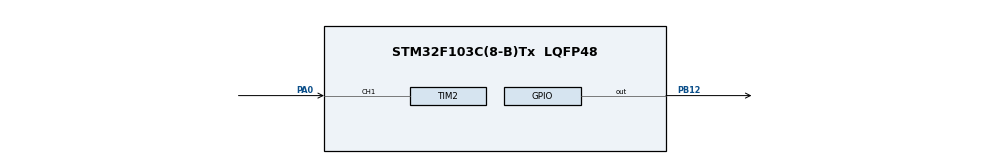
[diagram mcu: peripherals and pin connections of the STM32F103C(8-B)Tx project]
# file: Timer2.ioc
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Mcu.Family=STM32F1
Mcu.Name=STM32F103C(8-B)Tx
Mcu.Package=LQFP48
NVIC.PriorityGroup=NVIC_PRIORITYGROUP_4
PA0-WKUP.Signal=S_TIM2_CH1_ETR
PB12.Signal=GPIO_Output
ProjectManager.HeapSize=0x200
ProjectManager.StackSize=0x400
ProjectManager.TargetToolchain=MDK-ARM V4
RCC.APB1Freq_Value=8000000
RCC.APB2Freq_Value=8000000
SH.S_TIM2_CH1_ETR.0=TIM2_CH1,TriggerSource_TI1FP1
TIM2.Period=1000
TIM2.Slave_TriggerFilter=15
TIM2.Slave_TriggerPolarity=TIM_TRIGGERPOLARITY_RISING
VP_TIM2_VS_ControllerModeClock.Mode=Clock Mode
board=Timer2

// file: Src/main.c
/**
  ******************************************************************************
  * File Name          : main.c
  * Description        : Main program body
  ******************************************************************************
  *
  * COPYRIGHT(c) 2016 STMicroelectronics
  *
  * Redistribution and use in source and binary forms, with or without modification,
  * are permitted provided that the following conditions are met:
  *   1. Redistributions of source code must retain the above copyright notice,
  *      this list of conditions and the following disclaimer.
  *   2. Redistributions in binary form must reproduce the above copyright notice,
  *      this list of conditions and the following disclaimer in the documentation
  *      and/or other materials provided with the distribution.
  *   3. Neither the name of STMicroelectronics nor the names of its contributors
  *      may be used to endorse or promote products derived from this software
  *      without specific prior written permission.
  *
  * THIS SOFTWARE IS PROVIDED BY THE COPYRIGHT HOLDERS AND CONTRIBUTORS "AS IS"
  * AND ANY EXPRESS OR IMPLIED WARRANTIES, INCLUDING, BUT NOT LIMITED TO, THE
  * IMPLIED WARRANTIES OF MERCHANTABILITY AND FITNESS FOR A PARTICULAR PURPOSE ARE
  * DISCLAIMED. IN NO EVENT SHALL THE COPYRIGHT HOLDER OR CONTRIBUTORS BE LIABLE
  * FOR ANY DIRECT, INDIRECT, INCIDENTAL, SPECIAL, EXEMPLARY, OR CONSEQUENTIAL
  * DAMAGES (INCLUDING, BUT NOT LIMITED TO, PROCUREMENT OF SUBSTITUTE GOODS OR
  * SERVICES; LOSS OF USE, DATA, OR PROFITS; OR BUSINESS INTERRUPTION) HOWEVER
  * CAUSED AND ON ANY THEORY OF LIABILITY, WHETHER IN CONTRACT, STRICT LIABILITY,
  * OR TORT (INCLUDING NEGLIGENCE OR OTHERWISE) ARISING IN ANY WAY OUT OF THE USE
  * OF THIS SOFTWARE, EVEN IF ADVISED OF THE POSSIBILITY OF SUCH DAMAGE.
  *
  ******************************************************************************
  */
#include "stm32f1xx_hal.h"

TIM_HandleTypeDef htim2;

/* USER CODE BEGIN PV */
/* Private variables ---------------------------------------------------------*/
long count = 0;
/* USER CODE END PV */

void SystemClock_Config(void);
static void MX_GPIO_Init(void);
static void MX_TIM2_Init(void);

/* USER CODE BEGIN PFP */
/* Private function prototypes -----------------------------------------------*/

/* USER CODE END PFP */

int main(void)
{

  /* MCU Configuration----------------------------------------------------------*/

  /* Reset of all peripherals, Initializes the Flash interface and the Systick. */
  HAL_Init();

  /* Configure the system clock */
  SystemClock_Config();

  /* Initialize all configured peripherals */
  MX_GPIO_Init();
  MX_TIM2_Init();

  /* USER CODE BEGIN 2 */
	HAL_TIM_Base_Start(&htim2);// Khoi dong timer 2 khong su dung ngat
  /* USER CODE END 2 */

  /* Infinite loop */
  while (1)
  {
	count = __HAL_TIM_GetCounter(&htim2); // Doc gia tri bien count cua Timer2
  }

}

/** System Clock Configuration
*/
void SystemClock_Config(void)
{

  RCC_OscInitTypeDef RCC_OscInitStruct;
  RCC_ClkInitTypeDef RCC_ClkInitStruct;

  RCC_OscInitStruct.OscillatorType = RCC_OSCILLATORTYPE_HSI;
  RCC_OscInitStruct.HSIState = RCC_HSI_ON;
  RCC_OscInitStruct.HSICalibrationValue = 16;
  RCC_OscInitStruct.PLL.PLLState = RCC_PLL_NONE;
  HAL_RCC_OscConfig(&RCC_OscInitStruct);

  RCC_ClkInitStruct.ClockType = RCC_CLOCKTYPE_HCLK|RCC_CLOCKTYPE_SYSCLK
                              |RCC_CLOCKTYPE_PCLK1|RCC_CLOCKTYPE_PCLK2;
  RCC_ClkInitStruct.SYSCLKSource = RCC_SYSCLKSOURCE_HSI;
  RCC_ClkInitStruct.AHBCLKDivider = RCC_SYSCLK_DIV1;
  RCC_ClkInitStruct.APB1CLKDivider = RCC_HCLK_DIV1;
  RCC_ClkInitStruct.APB2CLKDivider = RCC_HCLK_DIV1;
  HAL_RCC_ClockConfig(&RCC_ClkInitStruct, FLASH_LATENCY_0);

  HAL_SYSTICK_Config(HAL_RCC_GetHCLKFreq()/1000);

  HAL_SYSTICK_CLKSourceConfig(SYSTICK_CLKSOURCE_HCLK);

  /* SysTick_IRQn interrupt configuration */
  HAL_NVIC_SetPriority(SysTick_IRQn, 0, 0);
}

/* TIM2 init function */
void MX_TIM2_Init(void)
{

  TIM_SlaveConfigTypeDef sSlaveConfig;
  TIM_MasterConfigTypeDef sMasterConfig;

  htim2.Instance = TIM2;
  htim2.Init.Prescaler = 0;
  htim2.Init.CounterMode = TIM_COUNTERMODE_UP;
  htim2.Init.Period = 1000;
  htim2.Init.ClockDivision = TIM_CLOCKDIVISION_DIV1;
  HAL_TIM_Base_Init(&htim2);

  sSlaveConfig.SlaveMode = TIM_SLAVEMODE_EXTERNAL1;
  sSlaveConfig.InputTrigger = TIM_TS_TI1FP1;
  sSlaveConfig.TriggerPolarity = TIM_TRIGGERPOLARITY_RISING;
  sSlaveConfig.TriggerFilter = 15;
  HAL_TIM_SlaveConfigSynchronization(&htim2, &sSlaveConfig);

  sMasterConfig.MasterOutputTrigger = TIM_TRGO_RESET;
  sMasterConfig.MasterSlaveMode = TIM_MASTERSLAVEMODE_DISABLE;
  HAL_TIMEx_MasterConfigSynchronization(&htim2, &sMasterConfig);

}

/** Configure pins as
        * Analog
        * Input
        * Output
        * EVENT_OUT
        * EXTI
*/
void MX_GPIO_Init(void)
{

  GPIO_InitTypeDef GPIO_InitStruct;

  /* GPIO Ports Clock Enable */
  __HAL_RCC_GPIOA_CLK_ENABLE();
  __HAL_RCC_GPIOB_CLK_ENABLE();

  /*Configure GPIO pin Output Level */
  HAL_GPIO_WritePin(GPIOB, GPIO_PIN_12, GPIO_PIN_RESET);

  /*Configure GPIO pin : PB12 */
  GPIO_InitStruct.Pin = GPIO_PIN_12;
  GPIO_InitStruct.Mode = GPIO_MODE_OUTPUT_PP;
  GPIO_InitStruct.Speed = GPIO_SPEED_FREQ_LOW;
  HAL_GPIO_Init(GPIOB, &GPIO_InitStruct);

}

/************************ (C) COPYRIGHT STMicroelectronics *****END OF FILE****/
